AUTOSAR XML (schema 4-2-2)
package /Components
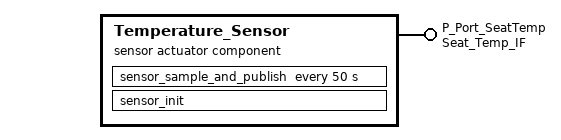
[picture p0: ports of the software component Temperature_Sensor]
  sensor actuator sw component type Temperature_Sensor
    provide port P_Port_SeatTemp: provided-interface=Seat_Temp_IF
    behavior Temperature_Sensor_Internal
      init event sensor_init_event: start-on-event=sensor_init
      timing event sensor_sampling_event: start-on-event=sensor_sample_and_publish, period=50
      runnable sensor_init
        data-send-points:
          4 x access:
            VA_Init_Seat1_Temp_A: accessed-variable=P_Port_SeatTemp.Seat1_Temp_A
            VA_Init_Seat1_Temp_B: accessed-variable=P_Port_SeatTemp.Seat1_Temp_B
            VA_Init_Seat2_Temp_A: accessed-variable=P_Port_SeatTemp.Seat2_Temp_A
            VA_Init_Seat2_Temp_B: accessed-variable=P_Port_SeatTemp.Seat2_Temp_B
      runnable sensor_sample_and_publish: minimum-start-interval=50
        data-send-points:
          4 x access:
            VA_Sample_Seat1_Temp_A: accessed-variable=P_Port_SeatTemp.Seat1_Temp_A
            VA_Sample_Seat1_Temp_B: accessed-variable=P_Port_SeatTemp.Seat1_Temp_B
            VA_Sample_Seat2_Temp_A: accessed-variable=P_Port_SeatTemp.Seat2_Temp_A
            VA_Sample_Seat2_Temp_B: accessed-variable=P_Port_SeatTemp.Seat2_Temp_B
